# nrf9230_enga_cellrf register map
Vendor: Nordic Semiconductor; Series: nRF92; File version: 1
CPU: CM0 r0p0, little endian, no MPU, no FPU, 2 interrupt priority bits, 33 interrupts
Registers are 32-bit, read-write, reset 0x0 unless marked. A register's access mark holds for its fields unless they carry their own. Offsets are from the block's base; [hi:lo] are bit positions; lines under a group give offsets from that group; {n}, {i} and the like mark numbered series; 'fields as' and 'values as' point back to an identical list.

## MVDMA — MVDMA performs direct-memory-accesses between memories. Data is transferred according to job descriptor lists. Each transfer has corresponding source and sink descriptor lists with matching data amounts. The lists are in memory and they contain data buffer information, address pointers, buffer sizes and data type attributes.
Base 0x4600B000
0x00 TASKS_PAUSE wo — Pause operation.
  [0] TASKS_PAUSE
    1=Trigger task
0x04 TASKS_RESET wo — Reset operation.
  [0] TASKS_RESET
    1=Trigger task
{0x8+4i} TASKS_START[{i}] (i=0..7) wo — Description collection: Start operation of job list n. Base address for successive TASKS_STARTs.
  [0] TASKS_START — Start operation of job list n. Base address for successive TASKS_STARTs.
    1=Trigger task
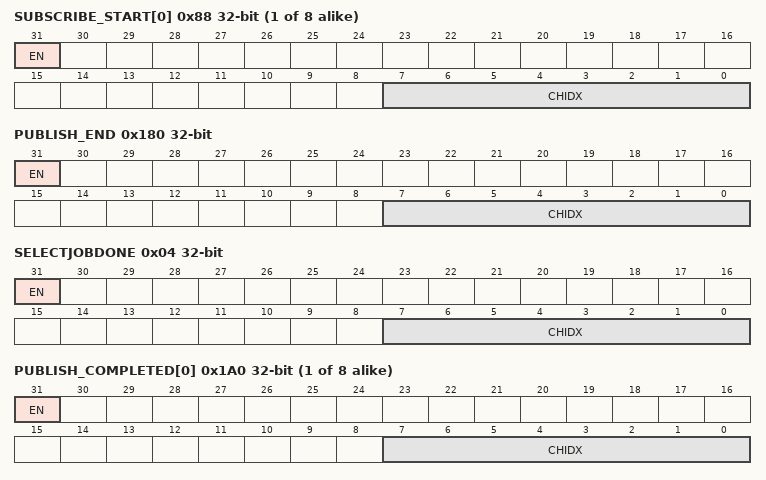
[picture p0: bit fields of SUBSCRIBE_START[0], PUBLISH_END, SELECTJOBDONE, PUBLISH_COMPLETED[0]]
{0x88+4i} SUBSCRIBE_START[{i}] (i=0..7) — Description collection: Subscribe configuration for task START[n]
  [31] EN
    0=Disabled (Disable subscription); 1=Enabled (Enable subscription)
  [7:0] CHIDX — DPPI channel that task START[n] will subscribe to
0x100 EVENTS_END — Event indicating that Sink data descriptor list has been completed.
  [0] EVENTS_END
    0=NotGenerated (Event not generated); 1=Generated (Event generated)
0x104 EVENTS_STARTED — Event indicating that the source list processing has started.
  [0] EVENTS_STARTED
    values as EVENTS_END.EVENTS_END
0x108 EVENTS_PAUSED — Event indicating that the data transfer has been paused.
  [0] EVENTS_PAUSED
    values as EVENTS_END.EVENTS_END
0x10C EVENTS_RESET — Event indicating that the peripheral has been reset.
  [0] EVENTS_RESET
    values as EVENTS_END.EVENTS_END
0x110 EVENTS_SOURCE group — Peripheral events.
  0x00 BUSERROR — Event indicating that a bus error has been received on the Source channel.
    [0] BUSERROR
      values as EVENTS_END.EVENTS_END
  0x04 SELECTJOBDONE — Event indicating that a job on the Source channel with EVENT_ENABLE active has been processed.
    [0] SELECTJOBDONE
      values as EVENTS_END.EVENTS_END
0x118 EVENTS_SINK group — Peripheral events.
  0x00 BUSERROR — Event indicating that a bus error has been received on the Sink channel.
    fields as EVENTS_SOURCE.BUSERROR
  0x04 SELECTJOBDONE — Event indicating that a job on the Sink channel with EVENT_ENABLE active has been processed.
    fields as EVENTS_SOURCE.SELECTJOBDONE
{0x120+4i} EVENTS_COMPLETED[{i}] (i=0..7) — Description collection: Event indicating that the operation started by the task START[n] has been completed. Base address for successive EVENTS_COMPLETED.
  [0] EVENTS_COMPLETED — Event indicating that the operation started by the task START[n] has been completed. Base address for successive EVENTS_COMPLETED.
    values as EVENTS_END.EVENTS_END
0x180 PUBLISH_END — Publish configuration for event END
  [31] EN
    0=Disabled (Disable publishing); 1=Enabled (Enable publishing)
  [7:0] CHIDX — DPPI channel that event END will publish to
0x190 PUBLISH_SOURCE group — Publish configuration for events
  0x04 SELECTJOBDONE — Publish configuration for event SOURCE.SELECTJOBDONE
    [31] EN
      values as PUBLISH_END.EN
    [7:0] CHIDX — DPPI channel that event SOURCE.SELECTJOBDONE will publish to
0x198 PUBLISH_SINK group — Publish configuration for events
  0x04 SELECTJOBDONE — Publish configuration for event SINK.SELECTJOBDONE
    [31] EN
      values as PUBLISH_END.EN
    [7:0] CHIDX — DPPI channel that event SINK.SELECTJOBDONE will publish to
{0x1A0+4i} PUBLISH_COMPLETED[{i}] (i=0..7) — Description collection: Publish configuration for event COMPLETED[n]
  [31] EN
    values as PUBLISH_END.EN
  [7:0] CHIDX — DPPI channel that event COMPLETED[n] will publish to
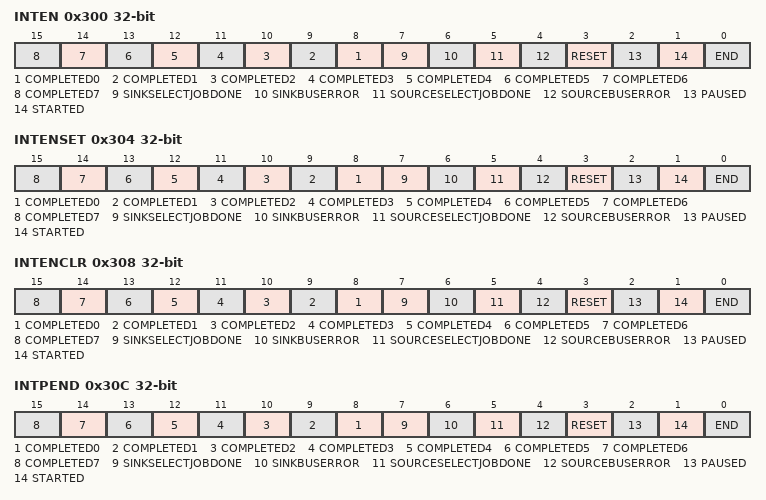
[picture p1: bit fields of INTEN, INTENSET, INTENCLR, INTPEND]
0x300 INTEN — Enable or disable interrupt
  [all] fields
    0=Disabled; 1=Enabled
  [n+8] COMPLETED{n} (n=0..7) — Enable or disable interrupt for event COMPLETED[{n}]
  [7] SINKSELECTJOBDONE — Enable or disable interrupt for event SINKSELECTJOBDONE
  [6] SINKBUSERROR — Enable or disable interrupt for event SINKBUSERROR
  [5] SOURCESELECTJOBDONE — Enable or disable interrupt for event SOURCESELECTJOBDONE
  [4] SOURCEBUSERROR — Enable or disable interrupt for event SOURCEBUSERROR
  [3] RESET — Enable or disable interrupt for event RESET
  [2] PAUSED — Enable or disable interrupt for event PAUSED
  [1] STARTED — Enable or disable interrupt for event STARTED
  [0] END — Enable or disable interrupt for event END
0x304 INTENSET — Enable interrupt
  [all] fields
    on read: 0=Disabled (Read: Disabled); 1=Enabled (Read: Enabled) | on write: 1=Set (Enable)
  [n+8] COMPLETED{n} (n=0..7) — Write '1' to enable interrupt for event COMPLETED[{n}]
  [7] SINKSELECTJOBDONE — Write '1' to enable interrupt for event SINKSELECTJOBDONE
  [6] SINKBUSERROR — Write '1' to enable interrupt for event SINKBUSERROR
  [5] SOURCESELECTJOBDONE — Write '1' to enable interrupt for event SOURCESELECTJOBDONE
  [4] SOURCEBUSERROR — Write '1' to enable interrupt for event SOURCEBUSERROR
  [3] RESET — Write '1' to enable interrupt for event RESET
  [2] PAUSED — Write '1' to enable interrupt for event PAUSED
  [1] STARTED — Write '1' to enable interrupt for event STARTED
  [0] END — Write '1' to enable interrupt for event END
0x308 INTENCLR — Disable interrupt
  [all] fields
    on read: 0=Disabled (Read: Disabled); 1=Enabled (Read: Enabled) | on write: 1=Clear (Disable)
  [n+8] COMPLETED{n} (n=0..7) — Write '1' to disable interrupt for event COMPLETED[{n}]
  [7] SINKSELECTJOBDONE — Write '1' to disable interrupt for event SINKSELECTJOBDONE
  [6] SINKBUSERROR — Write '1' to disable interrupt for event SINKBUSERROR
  [5] SOURCESELECTJOBDONE — Write '1' to disable interrupt for event SOURCESELECTJOBDONE
  [4] SOURCEBUSERROR — Write '1' to disable interrupt for event SOURCEBUSERROR
  [3] RESET — Write '1' to disable interrupt for event RESET
  [2] PAUSED — Write '1' to disable interrupt for event PAUSED
  [1] STARTED — Write '1' to disable interrupt for event STARTED
  [0] END — Write '1' to disable interrupt for event END
0x30C INTPEND ro — Pending interrupts
  [all] fields
    on read: 0=NotPending (Read: Not pending); 1=Pending (Read: Pending)
  [n+8] COMPLETED{n} (n=0..7) — Read pending status of interrupt for event COMPLETED[{n}]
  [7] SINKSELECTJOBDONE — Read pending status of interrupt for event SINKSELECTJOBDONE
  [6] SINKBUSERROR — Read pending status of interrupt for event SINKBUSERROR
  [5] SOURCESELECTJOBDONE — Read pending status of interrupt for event SOURCESELECTJOBDONE
  [4] SOURCEBUSERROR — Read pending status of interrupt for event SOURCEBUSERROR
  [3] RESET — Read pending status of interrupt for event RESET
  [2] PAUSED — Read pending status of interrupt for event PAUSED
  [1] STARTED — Read pending status of interrupt for event STARTED
  [0] END — Read pending status of interrupt for event END
0x400 STATUS group — MVDMA status registers.
  0x00 CRCRESULT ro — CRC checksum calculation result
    [31:0] CRC — Result
  0x04 FIFO ro — Status of intermediate fifo: empty, not empty and full information available.
    [1:0] FIFOSTATUS — Result
      0=Empty (Fifo is empty.); 1=NotEmpty (Fifo contains data.); 2=Full (Fifo is full.)
  0x08 ACTIVE ro — Status of DMA transfer.
    [0] ACTIVE — DMA activity
      0=Idle (DMA is in IDLE state.); 1=Active (Data being transferred.)
0x500 CONFIG group — MVDMA configuration registers.
  0x00 MODE — Configure MVDMA mode of operation.
    [0] MODE
      0=SingleMode (Registers SOURCE.LISTPTR and SINK.LISTPTR contain start address of a single job list.); 1=MultiMode (Registers SOURCE.LISTPTR and SINK.LISTPTR contain start address of a list of job list pointers in memory.)
  0x04 AXIMODE — Mode that defines if the AXI bus is AXI or AXI-Lite (one-beat bursts)
    [0] AXIMODE
      0=AXI (AXI burst transactions may be longer than one beat.); 1=AXILITE (All AXI transactions are one-beat accesses.)
0x600 SOURCE group — Source channel configuration and status.
  0x00 LISTPTR — Start address of Source job list or list of job list pointers, depending on value of CONFIG.MODE.
    [31:0] ADDRESS — Source job descriptor list address.
  0x04 BUSERROR ro — Source bus error status.
    [1:0] BUSERROR — Bus error type
      0=NoError (There are no errors.); 1=ReadError (Error related to memory when reading joblist, or error related to memory/register when reading data.); 2=ReadDecodeError (Error related to the joblist address when reading joblist, or error related to address when reading memory/register.)
  0x08 ADDRESS ro — Latest address being accessed on the Source channel.If a bus error occurs, these registers will contain the address that cause the error.
    [31:0] ADDRESS — Source address
  0x0C JOBCOUNT ro — Number of completed jobs in the current Source descriptor list. This resets to 0 when a new joblist is started.
    [31:0] COUNT — Source job count
0x620 SINK group — Sink channel configuration and status.
  0x00 LISTPTR — Start address of Sink job list or list of job list pointers, depending on value of CONFIG.MODE.
    [31:0] ADDRESS — Sink descriptor list address.
  0x04 BUSERROR ro — Sink bus error status.
    [2:0] BUSERROR — Bus error type
      0=NoError (There are no errors.); 1=ReadError (Error related to memory when reading joblist.); 2=ReadDecodeError (Error related to the joblist address when reading joblist.); 3=WriteError (Error related to memory/register when writing data.); 4=WriteDecodeError (Error related to the memory/register address when writing data.)
  0x08 ADDRESS ro — Latest address being accessed on the Sink channel. If a bus error occurs, these registers will contain the address that cause the error.
    [31:0] ADDRESS — Sink address
  0x0C JOBCOUNT ro — Number of completed jobs in the current Sink descriptor list. This resets to 0 when a new joblist is started.
    [31:0] COUNT — Sink job count

## GLOBAL_MVDMA120 — MVDMA performs direct-memory-accesses between memories. Data is transferred according to job descriptor lists. Each transfer has corresponding source and sink descriptor lists with matching data amounts. The lists are in memory and they contain data buffer information, address pointers, buffer sizes and data type attributes. 0
Base 0x5F8D9000
Same registers: GLOBAL_MVDMA121 0x5F8DC000
Registers as MVDMA; these are added or differ:
0x400 STATUS group — MVDMA status registers.
  0x00 CRCRESULT ro — CRC checksum calculation result
    [31:0] CRC — Result
  0x04 FIFO ro — Status of intermediate fifo: empty, not empty and full information available.
    [1:0] FIFOSTATUS — Result
      0=Empty (Fifo is empty.); 1=NotEmpty (Fifo contains data.); 2=Full (Fifo is full.)
  0x08 ACTIVE ro — Status of DMA transfer.
    [0] ACTIVE — DMA activity
      0=Idle (DMA is in IDLE state.); 1=Active (Data being transferred.)
0x500 CONFIG group — MVDMA configuration registers.
  0x00 MODE — Configure MVDMA mode of operation.
    fields as MVDMA.CONFIG.MODE
  0x04 AXIMODE — Mode that defines if the AXI bus is AXI or AXI-Lite (one-beat bursts)
    [0] AXIMODE
      0=AXI (AXI burst transactions may be longer than one beat.); 1=AXILITE (All AXI transactions are one-beat accesses.)
